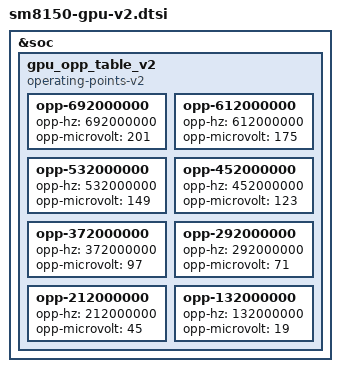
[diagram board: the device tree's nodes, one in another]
/* Copyright (c) 2018-2019, The Linux Foundation. All rights reserved.
 *
 * This program is free software; you can redistribute it and/or modify
 * it under the terms of the GNU General Public License version 2 and
 * only version 2 as published by the Free Software Foundation.
 *
 * This program is distributed in the hope that it will be useful,
 * but WITHOUT ANY WARRANTY; without even the implied warranty of
 * MERCHANTABILITY or FITNESS FOR A PARTICULAR PURPOSE.  See the
 * GNU General Public License for more details.
 */

&soc {
	gpu_opp_table_v2: gpu_opp_table_v2 {
		compatible = "operating-points-v2";

		opp-692000000 {
			opp-hz = /bits/ 64 <692000000>;
			opp-microvolt = <201>;
		};

		opp-612000000 {
			opp-hz = /bits/ 64 <612000000>;
			opp-microvolt = <175>;
		};

		opp-532000000 {
			opp-hz = /bits/ 64 <532000000>;
			opp-microvolt = <149>;
		};

		opp-452000000 {
			opp-hz = /bits/ 64 <452000000>;
			opp-microvolt = <123>;
		};

		opp-372000000 {
			opp-hz = /bits/ 64 <372000000>;
			opp-microvolt = <97>;
		};

		opp-292000000 {
			opp-hz = /bits/ 64 <292000000>;
			opp-microvolt = <71>;
		};
		opp-212000000 {
                        opp-hz = /bits/ 64 <212000000>;
                        opp-microvolt = <45>;
                };
		opp-132000000 {
                        opp-hz = /bits/ 64 <132000000>;
                        opp-microvolt = <19>;
                };
	};
};
